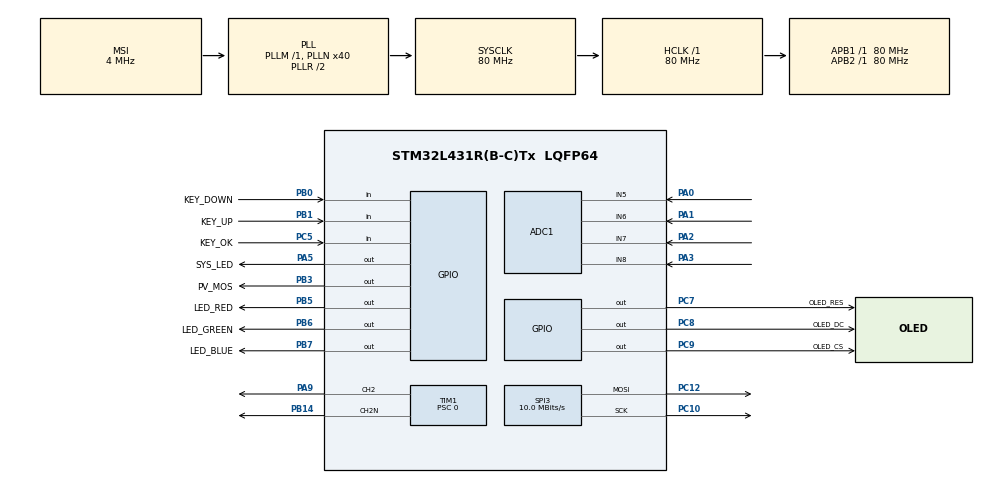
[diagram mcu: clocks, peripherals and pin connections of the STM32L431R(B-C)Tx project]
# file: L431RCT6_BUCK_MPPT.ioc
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ADC1.Channel-0\#ChannelRegularConversion=ADC_CHANNEL_5
ADC1.Channel-1\#ChannelRegularConversion=ADC_CHANNEL_6
ADC1.Channel-2\#ChannelRegularConversion=ADC_CHANNEL_7
ADC1.Channel-3\#ChannelRegularConversion=ADC_CHANNEL_8
ADC1.ContinuousConvMode=ENABLE
ADC1.DMAContinuousRequests=ENABLE
ADC1.NbrOfConversion=4
ADC1.NbrOfConversionFlag=1
ADC1.OffsetNumber-0\#ChannelRegularConversion=ADC_OFFSET_NONE
ADC1.OffsetNumber-1\#ChannelRegularConversion=ADC_OFFSET_NONE
ADC1.OffsetNumber-2\#ChannelRegularConversion=ADC_OFFSET_NONE
ADC1.OffsetNumber-3\#ChannelRegularConversion=ADC_OFFSET_NONE
ADC1.Rank-0\#ChannelRegularConversion=1
ADC1.Rank-1\#ChannelRegularConversion=2
ADC1.Rank-2\#ChannelRegularConversion=3
ADC1.Rank-3\#ChannelRegularConversion=4
ADC1.SamplingTime-0\#ChannelRegularConversion=ADC_SAMPLETIME_92CYCLES_5
ADC1.SamplingTime-1\#ChannelRegularConversion=ADC_SAMPLETIME_92CYCLES_5
ADC1.SamplingTime-2\#ChannelRegularConversion=ADC_SAMPLETIME_92CYCLES_5
ADC1.SamplingTime-3\#ChannelRegularConversion=ADC_SAMPLETIME_92CYCLES_5
ADC1.master=1
Dma.ADC1.0.Direction=DMA_PERIPH_TO_MEMORY
Dma.ADC1.0.Instance=DMA1_Channel1
Dma.ADC1.0.MemDataAlignment=DMA_MDATAALIGN_WORD
Dma.ADC1.0.MemInc=DMA_MINC_ENABLE
Dma.ADC1.0.Mode=DMA_CIRCULAR
Dma.ADC1.0.PeriphDataAlignment=DMA_PDATAALIGN_WORD
Dma.ADC1.0.PeriphInc=DMA_PINC_DISABLE
Dma.ADC1.0.Priority=DMA_PRIORITY_HIGH
Dma.Request0=ADC1
Dma.Request1=SPI3_TX
Dma.SPI3_TX.1.Direction=DMA_MEMORY_TO_PERIPH
Dma.SPI3_TX.1.Instance=DMA2_Channel2
Dma.SPI3_TX.1.MemDataAlignment=DMA_MDATAALIGN_BYTE
Dma.SPI3_TX.1.MemInc=DMA_MINC_ENABLE
Dma.SPI3_TX.1.Mode=DMA_NORMAL
Dma.SPI3_TX.1.PeriphDataAlignment=DMA_PDATAALIGN_BYTE
Dma.SPI3_TX.1.PeriphInc=DMA_PINC_DISABLE
Dma.SPI3_TX.1.Priority=DMA_PRIORITY_LOW
Mcu.Family=STM32L4
Mcu.Name=STM32L431R(B-C)Tx
Mcu.Package=LQFP64
NVIC.ADC1_IRQn=true\:0\:0\:false\:false\:true\:true\:true\:true
NVIC.DMA1_Channel1_IRQn=true\:0\:0\:false\:false\:true\:false\:true\:true
NVIC.DMA2_Channel2_IRQn=true\:0\:0\:false\:false\:true\:false\:true\:true
NVIC.PriorityGroup=NVIC_PRIORITYGROUP_4
NVIC.SPI3_IRQn=true\:2\:0\:true\:false\:true\:true\:true\:true
NVIC.TIM1_BRK_TIM15_IRQn=true\:0\:0\:false\:false\:true\:true\:true\:true
NVIC.TIM1_CC_IRQn=true\:0\:0\:false\:false\:true\:true\:true\:true
NVIC.TIM1_TRG_COM_IRQn=true\:0\:0\:false\:false\:true\:true\:true\:true
NVIC.TIM1_UP_TIM16_IRQn=true\:0\:0\:false\:false\:true\:true\:true\:true
PA0.Signal=ADCx_IN5
PA1.Signal=ADCx_IN6
PA13\ (JTMS-SWDIO).Mode=Serial_Wire
PA13\ (JTMS-SWDIO).Signal=SYS_JTMS-SWDIO
PA14\ (JTCK-SWCLK).Mode=Serial_Wire
PA14\ (JTCK-SWCLK).Signal=SYS_JTCK-SWCLK
PA2.Signal=ADCx_IN7
PA3.Signal=ADCx_IN8
PA5.GPIO_Label=SYS_LED
PA5.Signal=GPIO_Output
PA9.Signal=S_TIM1_CH2
PB0.GPIO_Label=KEY_DOWN
PB0.GPIO_PuPd=GPIO_PULLDOWN
PB0.Signal=GPIO_Input
PB1.GPIO_Label=KEY_UP
PB1.GPIO_PuPd=GPIO_PULLDOWN
PB1.Signal=GPIO_Input
PB10.Signal=USART3_TX
PB11.Signal=USART3_RX
PB14.Mode=PWM Generation2 CH2 CH2N
PB14.Signal=TIM1_CH2N
PB3\ (JTDO-TRACESWO).GPIO_Label=PV_MOS
PB3\ (JTDO-TRACESWO).GPIO_PuPd=GPIO_PULLDOWN
PB3\ (JTDO-TRACESWO).GPIO_Speed=GPIO_SPEED_FREQ_LOW
PB3\ (JTDO-TRACESWO).Signal=GPIO_Output
PB5.GPIO_Label=LED_RED
PB5.GPIO_PuPd=GPIO_PULLUP
PB5.Signal=GPIO_Output
PB6.GPIO_Label=LED_GREEN
PB6.GPIO_PuPd=GPIO_PULLUP
PB6.Signal=GPIO_Output
PB7.GPIO_Label=LED_BLUE
PB7.GPIO_PuPd=GPIO_PULLUP
PB7.Signal=GPIO_Output
PC10.Mode=TX_Only_Simplex_Unidirect_Master
PC10.Signal=SPI3_SCK
PC12.Mode=TX_Only_Simplex_Unidirect_Master
PC12.Signal=SPI3_MOSI
PC5.GPIO_Label=KEY_OK
PC5.GPIO_PuPd=GPIO_PULLDOWN
PC5.Signal=GPIO_Input
PC7.GPIO_Label=OLED_RES
PC7.Signal=GPIO_Output
PC8.GPIO_Label=OLED_DC
PC8.Signal=GPIO_Output
PC9.GPIO_Label=OLED_CS
PC9.Signal=GPIO_Output
PH0-OSC_IN\ (PH0).Mode=HSE-External-Oscillator
PH0-OSC_IN\ (PH0).Signal=RCC_OSC_IN
PH1-OSC_OUT\ (PH1).Mode=HSE-External-Oscillator
PH1-OSC_OUT\ (PH1).Signal=RCC_OSC_OUT
ProjectManager.HeapSize=0x200
ProjectManager.StackSize=0x400
ProjectManager.TargetToolchain=MDK-ARM V5.32
RCC.ADCFreq_Value=32000000
RCC.AHBFreq_Value=80000000
RCC.APB1Freq_Value=80000000
RCC.APB1TimFreq_Value=80000000
RCC.APB2Freq_Value=80000000
RCC.APB2TimFreq_Value=80000000
RCC.CortexFreq_Value=80000000
RCC.HCLKFreq_Value=80000000
RCC.HSE_VALUE=8000000
RCC.HSI48_VALUE=48000000
RCC.HSI_VALUE=16000000
RCC.LSE_VALUE=32768
RCC.MSI_VALUE=4000000
RCC.PLLN=40
RCC.PLLSAI1N=16
RCC.SYSCLKFreq_VALUE=80000000
RCC.SYSCLKSource=RCC_SYSCLKSOURCE_PLLCLK
RCC.VCOOutputFreq_Value=160000000
SH.ADCx_IN5.0=ADC1_IN5,IN5-Single-Ended
SH.ADCx_IN6.0=ADC1_IN6,IN6-Single-Ended
SH.ADCx_IN7.0=ADC1_IN7,IN7-Single-Ended
SH.ADCx_IN8.0=ADC1_IN8,IN8-Single-Ended
SH.S_TIM1_CH2.0=TIM1_CH2,PWM Generation2 CH2 CH2N
SPI3.BaudRatePrescaler=SPI_BAUDRATEPRESCALER_8
SPI3.CalculateBaudRate=10.0 MBits/s
SPI3.DataSize=SPI_DATASIZE_8BIT
SPI3.Direction=SPI_DIRECTION_2LINES
SPI3.Mode=SPI_MODE_MASTER
SPI3.VirtualType=VM_MASTER
TIM1.Channel-PWM\ Generation2\ CH2\ CH2N=TIM_CHANNEL_2
TIM1.DeadTime=12
TIM1.Period=2000-1
TIM1.Prescaler=0
VP_TIM1_VS_ClockSourceINT.Mode=Internal
board=custom

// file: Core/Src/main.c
/* USER CODE BEGIN Header */
/**
 ******************************************************************************
 * @file           : main.c
 * @brief          : Main program body
 ******************************************************************************
 * @attention
 *
 * Copyright (c) 2023 STMicroelectronics.
 * All rights reserved.
 *
 * This software is licensed under terms that can be found in the LICENSE file
 * in the root directory of this software component.
 * If no LICENSE file comes with this software, it is provided AS-IS.
 *
 ******************************************************************************
 */
/* USER CODE END Header */
#include "main.h"
#include "adc.h"
#include "dma.h"
#include "spi.h"
#include "tim.h"
#include "gpio.h"

/* USER CODE BEGIN Includes */

/* 自定义头文件 */
#include "app.h"

/* 自定义头文件 */

/* USER CODE END Includes */

void SystemClock_Config(void);

int main(void)
{

  /* MCU Configuration--------------------------------------------------------*/

  /* Reset of all peripherals, Initializes the Flash interface and the Systick. */
  HAL_Init();

  /* Configure the system clock */
  SystemClock_Config();

  /* Initialize all configured peripherals */
  MX_GPIO_Init();
  MX_DMA_Init();
  MX_ADC1_Init();
  MX_TIM1_Init();
  MX_SPI3_Init();
  /* USER CODE BEGIN 2 */

	OLED_Initialization();
    HAL_GPIO_WritePin(SYS_LED_GPIO_Port, SYS_LED_Pin, GPIO_PIN_RESET); /* 测试，在�?始的时�?�拉低一下系统灯 */

    HAL_ADC_Start_DMA(&hadc1, (uint32_t *)&ADC_Value, ADC_NUM);        /* �?始ADC的DMA转换*/

    // HAL_ADC_Start_DMA(&hadc1, (uint32_t *)&AD_Value_Filter, ADC_Channel_Num);
//
    MultiTimerInit();   /* 初始化定时器 */
    Button_init();      /* 按键功能初始�? */
    PID_Init(); //PID 的初始化
    led_Init();
  /* USER CODE END 2 */

  /* Infinite loop */
    while (1)
    {

    /* USER CODE BEGIN 3 */
        Timer_Loop(); /* 定时器循�? */
    }
  /* USER CODE END 3 */
}

void SystemClock_Config(void)
{
  RCC_OscInitTypeDef RCC_OscInitStruct = {0};
  RCC_ClkInitTypeDef RCC_ClkInitStruct = {0};

  /** Configure the main internal regulator output voltage
  */
  if (HAL_PWREx_ControlVoltageScaling(PWR_REGULATOR_VOLTAGE_SCALE1) != HAL_OK)
  {
    Error_Handler();
  }

  /** Initializes the RCC Oscillators according to the specified parameters
  * in the RCC_OscInitTypeDef structure.
  */
  RCC_OscInitStruct.OscillatorType = RCC_OSCILLATORTYPE_MSI;
  RCC_OscInitStruct.MSIState = RCC_MSI_ON;
  RCC_OscInitStruct.MSICalibrationValue = 0;
  RCC_OscInitStruct.MSIClockRange = RCC_MSIRANGE_6;
  RCC_OscInitStruct.PLL.PLLState = RCC_PLL_ON;
  RCC_OscInitStruct.PLL.PLLSource = RCC_PLLSOURCE_MSI;
  RCC_OscInitStruct.PLL.PLLM = 1;
  RCC_OscInitStruct.PLL.PLLN = 40;
  RCC_OscInitStruct.PLL.PLLP = RCC_PLLP_DIV7;
  RCC_OscInitStruct.PLL.PLLQ = RCC_PLLQ_DIV2;
  RCC_OscInitStruct.PLL.PLLR = RCC_PLLR_DIV2;
  if (HAL_RCC_OscConfig(&RCC_OscInitStruct) != HAL_OK)
  {
    Error_Handler();
  }

  /** Initializes the CPU, AHB and APB buses clocks
  */
  RCC_ClkInitStruct.ClockType = RCC_CLOCKTYPE_HCLK|RCC_CLOCKTYPE_SYSCLK
                              |RCC_CLOCKTYPE_PCLK1|RCC_CLOCKTYPE_PCLK2;
  RCC_ClkInitStruct.SYSCLKSource = RCC_SYSCLKSOURCE_PLLCLK;
  RCC_ClkInitStruct.AHBCLKDivider = RCC_SYSCLK_DIV1;
  RCC_ClkInitStruct.APB1CLKDivider = RCC_HCLK_DIV1;
  RCC_ClkInitStruct.APB2CLKDivider = RCC_HCLK_DIV1;

  if (HAL_RCC_ClockConfig(&RCC_ClkInitStruct, FLASH_LATENCY_4) != HAL_OK)
  {
    Error_Handler();
  }
}

void Error_Handler(void)
{
    __disable_irq();
    while (1)
    {
    }
}
